VERSION ""

NS_ :

BS_:
BU_: Main_Control_Unit BMS Motor_Controller Charge_Control_Unit
BO_ 204 GLV_Current: 4 Vector__XXX
   SG_ ECU_Current_Value : 0|16@1+ (0.01,0) [0|0] "A" Vector__XXX
   SG_ Cooling_Current_Value : 16|16@1+ (0.01,0) [0|0] "A" Vector__XXX

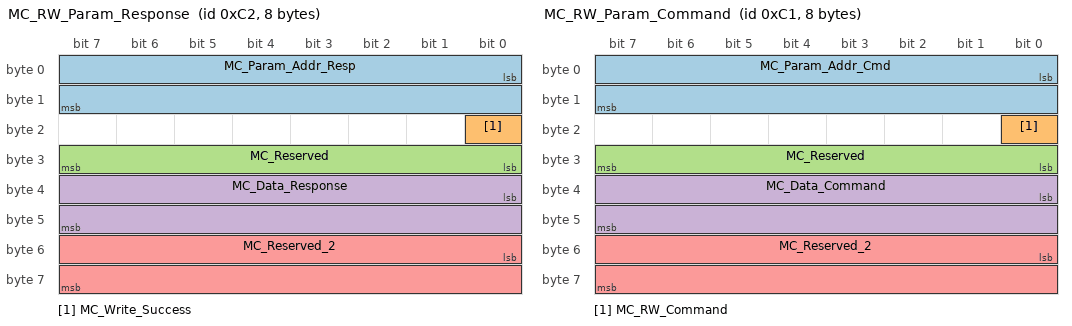
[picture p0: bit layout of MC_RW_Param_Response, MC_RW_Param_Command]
BO_ 194 MC_RW_Param_Response: 8 Vector__XXX
   SG_ MC_Param_Addr_Resp : 0|16@1+ (1,0) [0|0] "" Vector__XXX
   SG_ MC_Write_Success : 16|1@1+ (1,0) [0|0] "" Vector__XXX
   SG_ MC_Reserved : 24|8@1+ (1,0) [0|0] "" Vector__XXX
   SG_ MC_Data_Response : 32|16@1+ (1,0) [0|0] "" Vector__XXX
   SG_ MC_Reserved_2 : 48|16@1+ (1,0) [0|0] "" Vector__XXX

BO_ 193 MC_RW_Param_Command: 8 Vector__XXX
   SG_ MC_Param_Addr_Cmd : 0|16@1+ (1,0) [0|0] "" Vector__XXX
   SG_ MC_RW_Command : 16|1@1+ (1,0) [0|0] "" Vector__XXX
   SG_ MC_Reserved : 24|8@1+ (1,0) [0|0] "" Vector__XXX
   SG_ MC_Data_Command : 32|16@1+ (1,0) [0|0] "" Vector__XXX
   SG_ MC_Reserved_2 : 48|16@1+ (1,0) [0|0] "" Vector__XXX

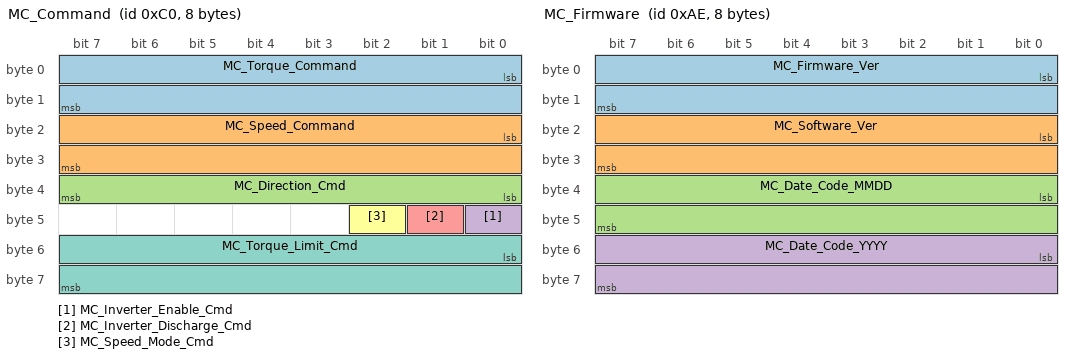
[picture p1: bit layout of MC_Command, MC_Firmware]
BO_ 192 MC_Command: 8 Vector__XXX
   SG_ MC_Torque_Command : 0|16@1- (0.1,0) [0|0] "NM" Vector__XXX
   SG_ MC_Speed_Command : 16|16@1- (1,0) [0|0] "RPM" Vector__XXX
   SG_ MC_Direction_Cmd : 32|8@1+ (1,0) [0|0] "" Vector__XXX
   SG_ MC_Inverter_Enable_Cmd : 40|1@1+ (1,0) [0|0] "" Vector__XXX
   SG_ MC_Inverter_Discharge_Cmd : 41|1@1+ (1,0) [0|0] "" Vector__XXX
   SG_ MC_Speed_Mode_Cmd : 42|1@1+ (1,0) [0|0] "" Vector__XXX
   SG_ MC_Torque_Limit_Cmd : 48|16@1+ (0.1,0) [0|0] "NM" Vector__XXX

BO_ 175 MC_Diagnostic_Data: 8 Vector__XXX
   SG_ MC_Diagnostic : 0|32@1+ (1,0) [0|0] "" Vector__XXX

BO_ 174 MC_Firmware: 8 Vector__XXX
   SG_ MC_Firmware_Ver : 0|16@1+ (1,0) [0|0] "" Vector__XXX
   SG_ MC_Software_Ver : 16|16@1+ (1,0) [0|0] "" Vector__XXX
   SG_ MC_Date_Code_MMDD : 32|16@1+ (1,0) [0|0] "" Vector__XXX
   SG_ MC_Date_Code_YYYY : 48|16@1+ (1,0) [0|0] "" Vector__XXX

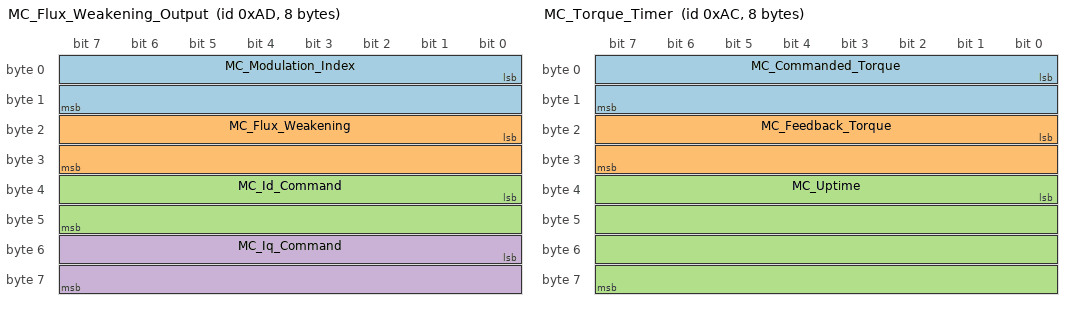
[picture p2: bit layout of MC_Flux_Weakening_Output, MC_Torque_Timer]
BO_ 173 MC_Flux_Weakening_Output: 8 Vector__XXX
   SG_ MC_Modulation_Index : 0|16@1+ (0.01,0) [0|0] "" Vector__XXX
   SG_ MC_Flux_Weakening : 16|16@1- (0.1,0) [0|0] "A" Vector__XXX
   SG_ MC_Id_Command : 32|16@1- (0.1,0) [0|0] "A" Vector__XXX
   SG_ MC_Iq_Command : 48|16@1- (0.1,0) [0|0] "A" Vector__XXX

BO_ 172 MC_Torque_Timer: 8 Vector__XXX
   SG_ MC_Commanded_Torque : 0|16@1- (0.1,0) [0|0] "NM" Vector__XXX
   SG_ MC_Feedback_Torque : 16|16@1- (0.1,0) [0|0] "NM" Vector__XXX
   SG_ MC_Uptime : 32|32@1+ (0.003,0) [0|0] "sec" Vector__XXX

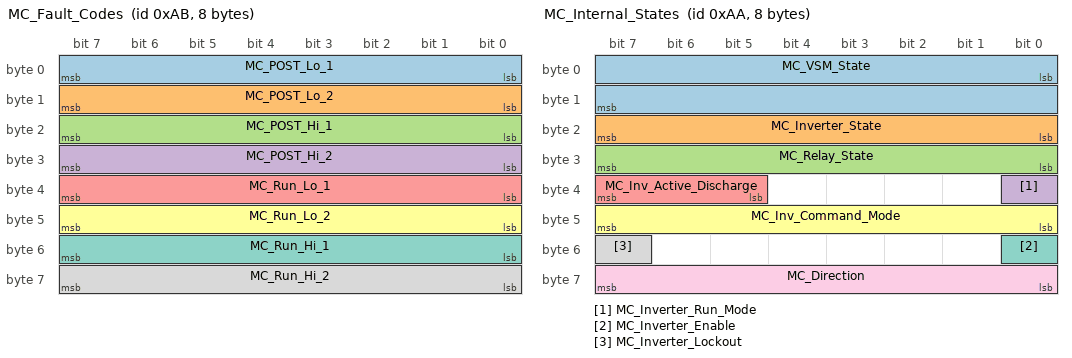
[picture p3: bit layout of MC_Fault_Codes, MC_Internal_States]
BO_ 171 MC_Fault_Codes: 8 Vector__XXX
   SG_ MC_POST_Lo_1 : 0|8@1+ (1,0) [0|0] "" Vector__XXX
   SG_ MC_POST_Lo_2 : 8|8@1+ (1,0) [0|0] "" Vector__XXX
   SG_ MC_POST_Hi_1 : 16|8@1+ (1,0) [0|0] "" Vector__XXX
   SG_ MC_POST_Hi_2 : 24|8@1+ (1,0) [0|0] "" Vector__XXX
   SG_ MC_Run_Lo_1 : 32|8@1+ (1,0) [0|0] "" Vector__XXX
   SG_ MC_Run_Lo_2 : 40|8@1+ (1,0) [0|0] "" Vector__XXX
   SG_ MC_Run_Hi_1 : 48|8@1+ (1,0) [0|0] "" Vector__XXX
   SG_ MC_Run_Hi_2 : 56|8@1+ (1,0) [0|0] "" Vector__XXX

BO_ 170 MC_Internal_States: 8 Vector__XXX
   SG_ MC_VSM_State : 0|16@1+ (1,0) [0|0] "" Vector__XXX
   SG_ MC_Inverter_State : 16|8@1+ (1,0) [0|0] "" Vector__XXX
   SG_ MC_Relay_State : 24|8@1+ (1,0) [0|0] "" Vector__XXX
   SG_ MC_Inverter_Run_Mode : 32|1@1+ (1,0) [0|0] "" Vector__XXX
   SG_ MC_Inv_Active_Discharge : 37|3@1+ (1,0) [0|0] "" Vector__XXX
   SG_ MC_Inv_Command_Mode : 40|8@1+ (1,0) [0|0] "" Vector__XXX
   SG_ MC_Inverter_Enable : 48|1@1+ (1,0) [0|0] "" Vector__XXX
   SG_ MC_Inverter_Lockout : 55|1@1+ (1,0) [0|0] "" Vector__XXX
   SG_ MC_Direction : 56|8@1+ (1,0) [0|0] "" Vector__XXX

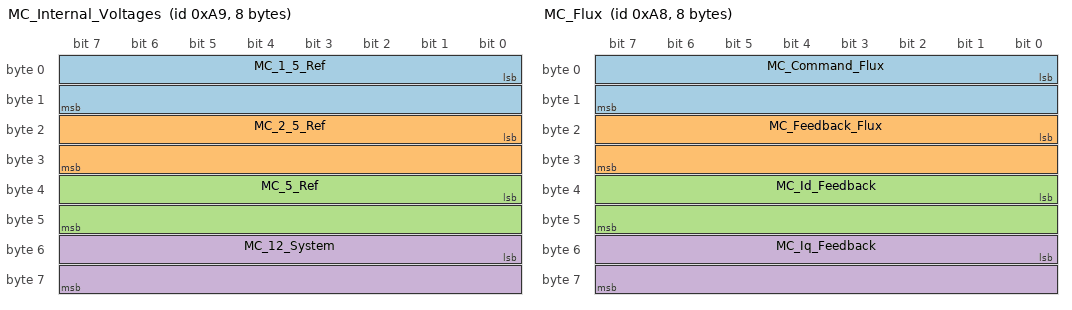
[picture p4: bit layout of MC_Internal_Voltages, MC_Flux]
BO_ 169 MC_Internal_Voltages: 8 Vector__XXX
   SG_ MC_1_5_Ref : 0|16@1- (0.01,0) [0|0] "V" Vector__XXX
   SG_ MC_2_5_Ref : 16|16@1- (0.01,0) [0|0] "V" Vector__XXX
   SG_ MC_5_Ref : 32|16@1- (0.01,0) [0|0] "V" Vector__XXX
   SG_ MC_12_System : 48|16@1- (0.01,0) [0|0] "V" Vector__XXX

BO_ 168 MC_Flux: 8 Vector__XXX
   SG_ MC_Command_Flux : 0|16@1- (0.001,0) [0|0] "" Vector__XXX
   SG_ MC_Feedback_Flux : 16|16@1- (0.001,0) [0|0] "" Vector__XXX
   SG_ MC_Id_Feedback : 32|16@1- (0.1,0) [0|0] "A" Vector__XXX
   SG_ MC_Iq_Feedback : 48|16@1- (0.1,0) [0|0] "A" Vector__XXX

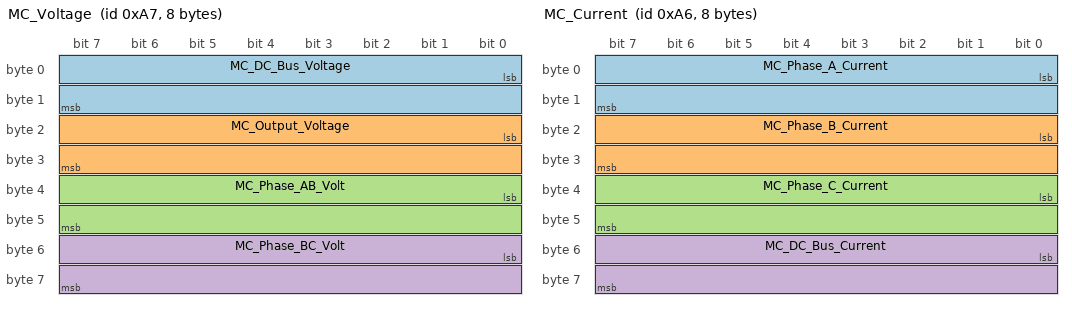
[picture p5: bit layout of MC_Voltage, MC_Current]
BO_ 167 MC_Voltage: 8 Vector__XXX
   SG_ MC_DC_Bus_Voltage : 0|16@1- (0.1,0) [0|0] "V" Vector__XXX
   SG_ MC_Output_Voltage : 16|16@1- (0.1,0) [0|0] "V" Vector__XXX
   SG_ MC_Phase_AB_Volt : 32|16@1- (0.1,0) [0|0] "V" Vector__XXX
   SG_ MC_Phase_BC_Volt : 48|16@1- (0.1,0) [0|0] "V" Vector__XXX

BO_ 166 MC_Current: 8 Vector__XXX
   SG_ MC_Phase_A_Current : 0|16@1- (0.1,0) [0|0] "A" Vector__XXX
   SG_ MC_Phase_B_Current : 16|16@1- (0.1,0) [0|0] "A" Vector__XXX
   SG_ MC_Phase_C_Current : 32|16@1- (0.1,0) [0|0] "A" Vector__XXX
   SG_ MC_DC_Bus_Current : 48|16@1- (0.1,0) [0|0] "A" Vector__XXX

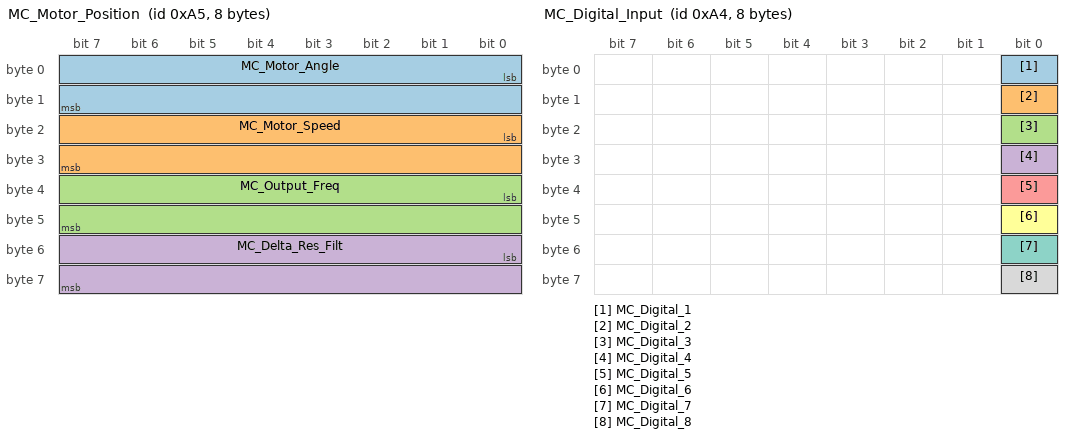
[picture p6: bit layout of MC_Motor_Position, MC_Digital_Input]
BO_ 165 MC_Motor_Position: 8 Vector__XXX
   SG_ MC_Motor_Angle : 0|16@1- (0.1,0) [0|0] "" Vector__XXX
   SG_ MC_Motor_Speed : 16|16@1- (1,0) [0|0] "RPM" Vector__XXX
   SG_ MC_Output_Freq : 32|16@1- (0.1,0) [0|0] "" Vector__XXX
   SG_ MC_Delta_Res_Filt : 48|16@1- (0.1,0) [0|0] "" Vector__XXX

BO_ 164 MC_Digital_Input: 8 Vector__XXX
   SG_ MC_Digital_1 : 0|1@1+ (1,0) [0|0] "" Vector__XXX
   SG_ MC_Digital_2 : 8|1@1+ (1,0) [0|0] "" Vector__XXX
   SG_ MC_Digital_3 : 16|1@1+ (1,0) [0|0] "" Vector__XXX
   SG_ MC_Digital_4 : 24|1@1+ (1,0) [0|0] "" Vector__XXX
   SG_ MC_Digital_5 : 32|1@1+ (1,0) [0|0] "" Vector__XXX
   SG_ MC_Digital_6 : 40|1@1+ (1,0) [0|0] "" Vector__XXX
   SG_ MC_Digital_7 : 48|1@1+ (1,0) [0|0] "" Vector__XXX
   SG_ MC_Digital_8 : 56|1@1+ (1,0) [0|0] "" Vector__XXX

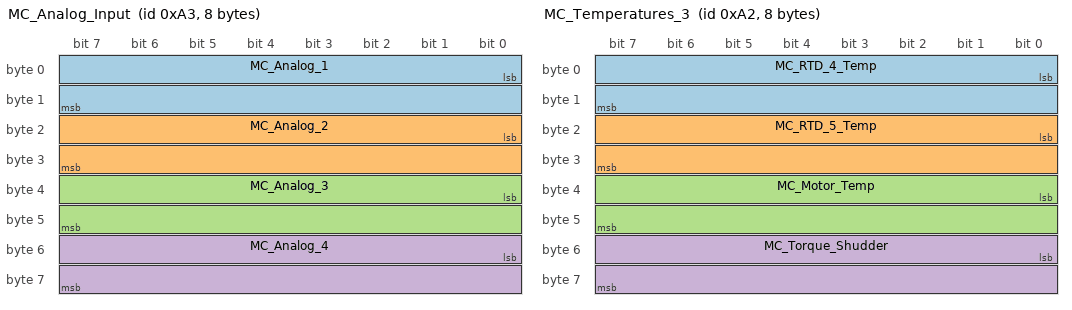
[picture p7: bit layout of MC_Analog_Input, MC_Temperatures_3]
BO_ 163 MC_Analog_Input: 8 Vector__XXX
   SG_ MC_Analog_1 : 0|16@1- (0.01,0) [0|0] "V" Vector__XXX
   SG_ MC_Analog_2 : 16|16@1- (0.01,0) [0|0] "V" Vector__XXX
   SG_ MC_Analog_3 : 32|16@1- (0.01,0) [0|0] "V" Vector__XXX
   SG_ MC_Analog_4 : 48|16@1+ (0.01,0) [0|0] "V" Vector__XXX

BO_ 162 MC_Temperatures_3: 8 Vector__XXX
   SG_ MC_RTD_4_Temp : 0|16@1- (0.1,0) [0|0] "C" Vector__XXX
   SG_ MC_RTD_5_Temp : 16|16@1- (0.1,0) [0|0] "C" Vector__XXX
   SG_ MC_Motor_Temp : 32|16@1- (0.1,0) [0|0] "C" Vector__XXX
   SG_ MC_Torque_Shudder : 48|16@1- (0.1,0) [0|0] "Nm" Vector__XXX

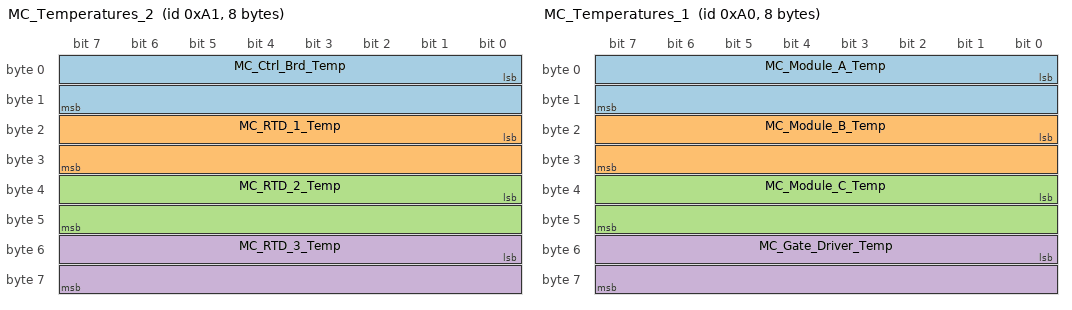
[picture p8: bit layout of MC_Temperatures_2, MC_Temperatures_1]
BO_ 161 MC_Temperatures_2: 8 Vector__XXX
   SG_ MC_Ctrl_Brd_Temp : 0|16@1- (0.1,0) [0|0] "C" Vector__XXX
   SG_ MC_RTD_1_Temp : 16|16@1- (0.1,0) [0|0] "C" Vector__XXX
   SG_ MC_RTD_2_Temp : 32|16@1- (0.1,0) [0|0] "C" Vector__XXX
   SG_ MC_RTD_3_Temp : 48|16@1- (0.1,0) [0|0] "C" Vector__XXX

BO_ 160 MC_Temperatures_1: 8 Vector__XXX
   SG_ MC_Module_A_Temp : 0|16@1- (1,0) [0|0] "C" Vector__XXX
   SG_ MC_Module_B_Temp : 16|16@1- (0.1,0) [0|0] "C" Vector__XXX
   SG_ MC_Module_C_Temp : 32|16@1- (0.1,0) [0|0] "" Vector__XXX
   SG_ MC_Gate_Driver_Temp : 48|16@1- (0.1,0) [0|0] "C" Vector__XXX

BO_ 221 CCU_Status: 1 Vector__XXX
   SG_ Charger_Enabled : 0|1@1+ (1,0) [0|1] "" Vector__XXX

BO_ 226 BMS_Coulomb_Counts: 8 Vector__XXX
   SG_ BMS_Total_Charge : 0|32@1+ (0.0001,0) [0|0] "C" Vector__XXX
   SG_ BMS_Total_Discharge : 32|32@1+ (0.0001,0) [0|0] "C" Vector__XXX

BO_ 222 BMS_Balancing_Status: 7 Vector__XXX
   SG_ BMS_Group_ID : 0|1@1+ (1,0) [0|1] "" Vector__XXX
   SG_ BMS_Bal_Status : 1|55@1+ (1,0) [0|0] "" Vector__XXX

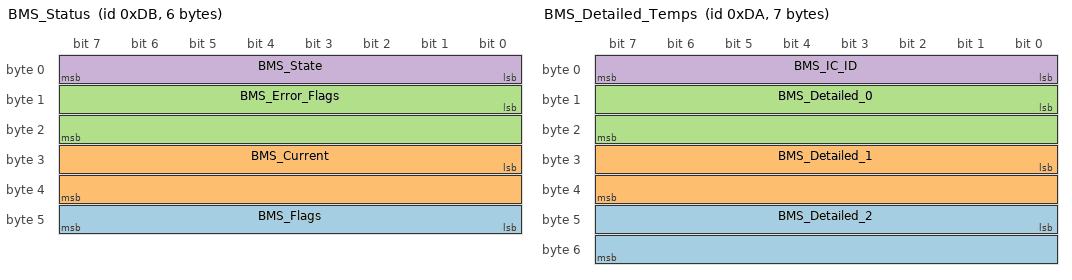
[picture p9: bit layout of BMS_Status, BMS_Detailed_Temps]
BO_ 219 BMS_Status: 6 Vector__XXX
   SG_ BMS_Flags : 40|8@1+ (1,0) [0|255] "" Vector__XXX
   SG_ BMS_Current : 24|16@1- (0.01,0) [-327.68|327.67] "A" Vector__XXX
   SG_ BMS_Error_Flags : 8|16@1+ (1,0) [0|65535] "" Vector__XXX
   SG_ BMS_State : 0|8@1+ (1,0) [0|255] "" Vector__XXX

BO_ 218 BMS_Detailed_Temps: 7 Vector__XXX
   SG_ BMS_Detailed_2 : 40|16@1- (0.01,0) [-327.68|327.67] "C" Vector__XXX
   SG_ BMS_Detailed_1 : 24|16@1- (0.01,0) [-327.68|327.67] "C" Vector__XXX
   SG_ BMS_Detailed_0 : 8|16@1- (0.01,0) [-327.68|327.67] "C" Vector__XXX
   SG_ BMS_IC_ID : 0|8@1+ (1,0) [0|255] "" Vector__XXX

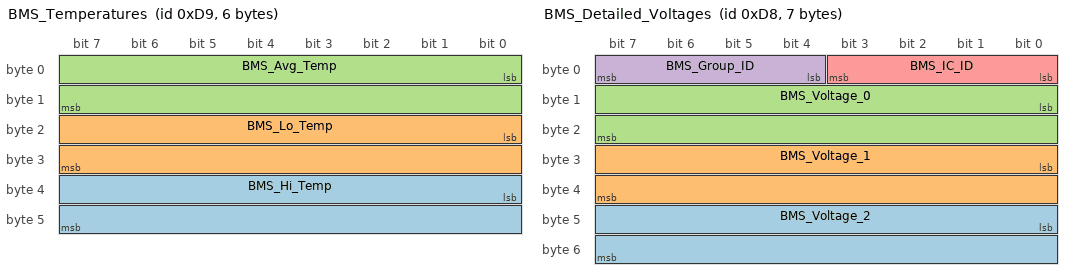
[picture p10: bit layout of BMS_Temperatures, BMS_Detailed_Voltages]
BO_ 217 BMS_Temperatures: 6 Vector__XXX
   SG_ BMS_Hi_Temp : 32|16@1- (0.01,0) [-327.68|327.67] "C" Vector__XXX
   SG_ BMS_Lo_Temp : 16|16@1- (0.01,0) [-327.68|327.67] "C" Vector__XXX
   SG_ BMS_Avg_Temp : 0|16@1- (0.01,0) [-327.68|327.67] "C" Vector__XXX

BO_ 216 BMS_Detailed_Voltages: 7 Vector__XXX
   SG_ BMS_Voltage_2 : 40|16@1+ (0.001,0) [0|65.535] "V" Vector__XXX
   SG_ BMS_Voltage_1 : 24|16@1+ (0.001,0) [0|65.535] "V" Vector__XXX
   SG_ BMS_Voltage_0 : 8|16@1+ (0.001,0) [0|65.535] "V" Vector__XXX
   SG_ BMS_Group_ID : 4|4@1+ (1,0) [0|15] "" Vector__XXX
   SG_ BMS_IC_ID : 0|4@1+ (1,0) [0|15] "" Vector__XXX

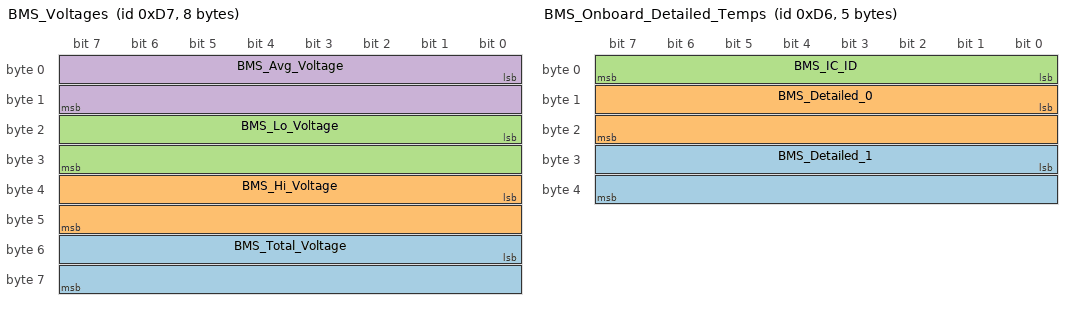
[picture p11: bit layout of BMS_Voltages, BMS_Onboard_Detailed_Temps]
BO_ 215 BMS_Voltages: 8 Vector__XXX
   SG_ BMS_Total_Voltage : 48|16@1+ (0.01,0) [0|655.35] "V" Vector__XXX
   SG_ BMS_Hi_Voltage : 32|16@1+ (0.001,0) [0|65.535] "V" Vector__XXX
   SG_ BMS_Lo_Voltage : 16|16@1+ (0.001,0) [0|65.535] "V" Vector__XXX
   SG_ BMS_Avg_Voltage : 0|16@1+ (0.001,0) [0|65.535] "V" Vector__XXX

BO_ 214 BMS_Onboard_Detailed_Temps: 5 Vector__XXX
   SG_ BMS_Detailed_1 : 24|16@1- (0.01,0) [-327.68|327.67] "C" Vector__XXX
   SG_ BMS_Detailed_0 : 8|16@1- (0.01,0) [-327.68|327.67] "C" Vector__XXX
   SG_ BMS_IC_ID : 0|8@1+ (1,0) [0|255] "" Vector__XXX

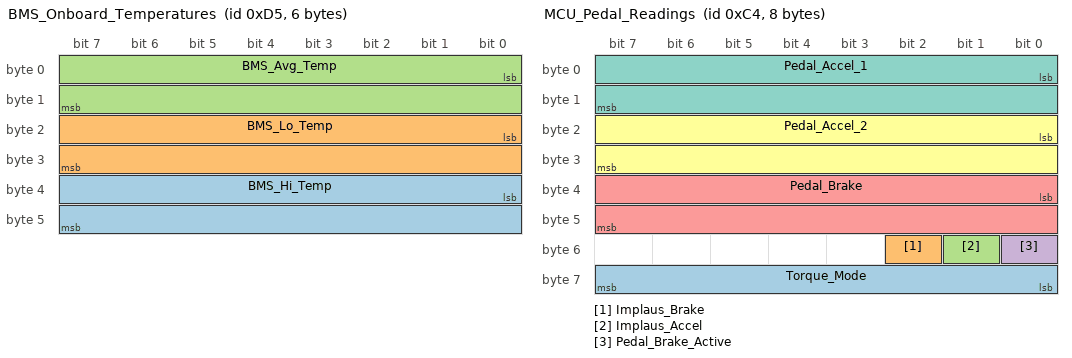
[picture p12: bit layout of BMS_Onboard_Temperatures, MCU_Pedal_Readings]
BO_ 213 BMS_Onboard_Temperatures: 6 Vector__XXX
   SG_ BMS_Hi_Temp : 32|16@1- (0.01,0) [-327.68|327.67] "C" Vector__XXX
   SG_ BMS_Lo_Temp : 16|16@1- (0.01,0) [-327.68|327.67] "C" Vector__XXX
   SG_ BMS_Avg_Temp : 0|16@1- (0.01,0) [-327.68|327.67] "C" Vector__XXX

BO_ 196 MCU_Pedal_Readings: 8 Main_Control_Unit
   SG_ Torque_Mode : 56|8@1+ (1,0) [0|255] "" Vector__XXX
   SG_ Implaus_Brake : 50|1@1+ (1,0) [0|1] "" Vector__XXX
   SG_ Implaus_Accel : 49|1@1+ (1,0) [0|1] "" Vector__XXX
   SG_ Pedal_Brake_Active : 48|1@1+ (1,0) [0|1] "" Vector__XXX
   SG_ Pedal_Brake : 32|16@1+ (1,0) [0|65535] "" Vector__XXX
   SG_ Pedal_Accel_2 : 16|16@1+ (1,0) [0|65535] "" Vector__XXX
   SG_ Pedal_Accel_1 : 0|16@1+ (1,0) [0|65535] "" Vector__XXX

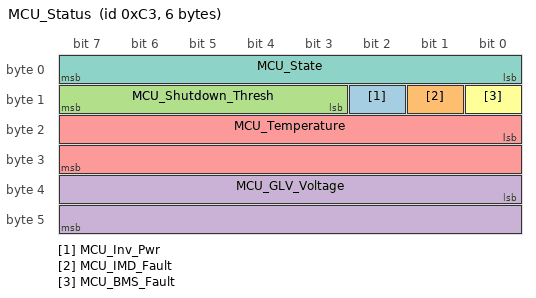
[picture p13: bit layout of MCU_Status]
BO_ 195 MCU_Status: 6 Main_Control_Unit
   SG_ MCU_Inv_Pwr : 10|1@1+ (1,0) [0|1] "" Vector__XXX
   SG_ MCU_IMD_Fault : 9|1@1+ (1,0) [0|1] "" Vector__XXX
   SG_ MCU_Shutdown_Thresh : 11|5@1+ (1,0) [0|31] "" Vector__XXX
   SG_ MCU_GLV_Voltage : 32|16@1+ (0.01,0) [0|655.35] "V" Vector__XXX
   SG_ MCU_Temperature : 16|16@1- (1,0) [-32768|32767] "C" Vector__XXX
   SG_ MCU_BMS_Fault : 8|1@1+ (1,0) [0|1] "" Vector__XXX
   SG_ MCU_State : 0|8@1+ (1,0) [0|255] "" Vector__XXX

BA_DEF_ BO_ "GenMsgBackgroundColor" STRING ;
BA_DEF_ BO_ "GenMsgForegroundColor" STRING ;
BA_DEF_DEF_ "GenMsgBackgroundColor" "#ffffff";
BA_DEF_DEF_ "GenMsgForegroundColor" "#000000";
VAL_ 194 MC_Write_Success 0 "Not_written" 1 "Success" 0 "No Description";
VAL_ 193 MC_RW_Command 0 "Read" 1 "Write";
VAL_ 192 MC_Direction_Cmd 0 "Reverse" 1 "Forward";
VAL_ 192 MC_Inverter_Enable_Cmd 0 "Inverter_Off" 1 "Inverter_On";
VAL_ 192 MC_Inverter_Discharge_Cmd 0 "Disable_Discharge" 1 "Enable_Discharge";
VAL_ 192 MC_Speed_Mode_Cmd 0 "Do_not_override_mode" 1 "Override_to_speed_mode";
VAL_ 171 MC_POST_Lo_1 1 "HW_Gate/Desaturation_Fault" 2 "HW_Overcurrent_Fault" 4 "Accelerator_Short" 8 "Accelerator_Open" 16 "Current_Sensor_Low" 32 "Current_Sensor_High" 64 "Module_Temperature_Low" 128 "Module_Temperature_High";
VAL_ 171 MC_POST_Lo_2 1 "Control_PCB_Temp_Low" 2 "Control_PCB_Temp_High" 4 "Gate_Drive_PCB_Temp_Low" 8 "Gate_Drive_PCB_Temp_High" 16 "5v_Sense_Voltage_Low" 32 "5v_Sense_Voltage_High" 64 "12v_Sense_Voltage_Low" 128 "12v_Sense_Voltage_High";
VAL_ 171 MC_POST_Hi_1 1 "2.5v_Sense_Voltage_Low" 2 "2.5v_Sense_Voltage_High" 4 "1.5v_Sense_Voltage_Low" 8 "1.5v_Sense_Voltage_High" 16 "DC_Bus_Voltage_Low" 32 "DC_Bus_Voltage_High" 64 "Pre-charge_Timeout" 128 "Pre-charge_Voltage_Failure";
VAL_ 171 MC_POST_Hi_2 1 "EEPROM_Checksum_Invalid" 2 "EEPROM_Data_Out_of_Range" 4 "EEPROM_Update_Required" 8 "Reserved" 16 "Reserved" 32 "Reserved" 64 "Brake_Short" 128 "Brake_Open";
VAL_ 171 MC_Run_Lo_1 1 "Motor_Overspeed" 2 "Overcurrent" 4 "Overvoltage" 8 "Inverter_Overtemperature" 16 "Accelerator_Input_Short" 32 "Accelerator_Input_Open" 64 "Direction_Command_Fault" 128 "Inverter_Response_Timeout";
VAL_ 171 MC_Run_Lo_2 1 "HW_Gate/Desaturation_Fault" 2 "Hardware_Overcurrent" 4 "Undervoltage" 8 "CAN_Command_Msg_Lost" 16 "Motor_Overtemperature" 32 "Reserved" 64 "Reserved" 128 "Reserved";
VAL_ 171 MC_Run_Hi_1 1 "Brake_Input_Short" 2 "Brake_Input_Open" 4 "Module_A_Overtemperature" 8 "Module_B_Overtemperature" 16 "Module_C_Overtemperature" 32 "PCB_Overtemperature" 64 "Gate_Drive_Board_1_Overtemperature" 128 "Gate_Drive_Board_2_Overtemperature" 0 "No Description";
VAL_ 171 MC_Run_Hi_2 1 "Gate_Drive_Board_3_Overtemperature" 2 "Current_Sensor_Fault" 4 "Reserved" 8 "Reserved" 16 "Reserved" 32 "Reserved" 64 "Resolver_Not_Connected" 128 "Inverter_Discharge_Active";
VAL_ 170 MC_VSM_State 0 "VSM_Start" 1 "Pre-Charge_Init" 2 "Pre-Charge_Active" 3 "Pre-Charge_Complete" 4 "VSM_Wait" 5 "VSM_Ready" 6 "Motor_Running" 7 "Blink_Fault" 14 "Shutdown_In_Progress" 15 "Recycle_Power";
VAL_ 170 MC_Inverter_State 0 "Power_On" 1 "Stopped" 2 "Open_Loop" 3 "Closed_Loop" 4 "Wait" 5 "Internal" 6 "Internal" 7 "Internal" 8 "Idle_Run" 9 "Idle_Stop" 10 "Internal" 11 "Internal" 12 "Internal";
VAL_ 170 MC_Inverter_Run_Mode 0 "Torque_Mode" 1 "Speed_Mode";
VAL_ 170 MC_Inv_Active_Discharge 0 "Discharge_Disabled" 1 "Discharge_Enabled,_waiting" 2 "Performing_Speed_Check" 3 "Discharge_Actively_Occurring" 4 "Discharge_Completed";
VAL_ 170 MC_Inv_Command_Mode 0 "CAN_mode" 1 "VSM_mode";
VAL_ 170 MC_Inverter_Enable 0 "Inverter_Disabled" 1 "Inverter_Enabled";
VAL_ 170 MC_Inverter_Lockout 0 "Lockout_Not_Active" 1 "Lockout_Active";
VAL_ 170 MC_Direction 0 "Reverse/Stopped" 1 "Forward";
VAL_ 219 BMS_Error_Flags 256 "Onboard Overtemp" 128 "Undertemp" 64 "Charge Overtemp" 32 "Discharge Overtemp" 16 "Charge Overcurrent" 8 "Discharge Overcurrent" 4 "Total voltage high" 2 "Undervoltage" 1 "Overvoltage" 0 "Normal";
VAL_ 219 BMS_State 4 "Balancing - Overheated" 3 "Balancing" 2 "Charging" 1 "Discharging";
VAL_ 214 BMS_IC_ID 0 "No Description";
VAL_ 195 MCU_IMD_Fault 1 "Faulted" 0 "Normal";
VAL_ 195 MCU_Shutdown_Thresh 16 "Shutdown F above threshold" 8 "Shutdown E above threshold" 4 "Shutdown D above threshold" 2 "Shutdown C above threshold" 1 "Shutdown B above threshold" 0 "Normal";
VAL_ 195 MCU_BMS_Fault 1 "Faulted" 0 "Normal";
VAL_ 195 MCU_State 5 "Ready to drive" 4 "Waiting for ready-to-drive" 3 "Enabling inverter" 2 "Tractive system active" 1 "Tractive system not active";
